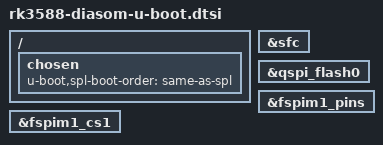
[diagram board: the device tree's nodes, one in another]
#include "rk3588-u-boot.dtsi"

/ {
	chosen {
		u-boot,spl-boot-order = "same-as-spl", &sdmmc, &sdhci;
	};
};

&sfc {
	bootph-pre-ram;
};

&qspi_flash0 {
	bootph-pre-ram;
};

&fspim1_pins {
	bootph-pre-ram;
};

&fspim1_cs1 {
	bootph-pre-ram;
};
